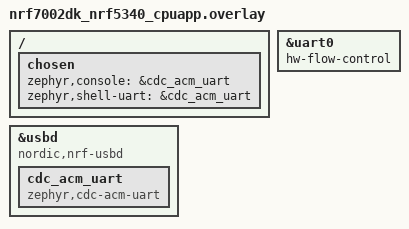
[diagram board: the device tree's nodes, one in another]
/*
 * Copyright (c) 2023 Nordic Semiconductor ASA
 *
 * SPDX-License-Identifier: LicenseRef-Nordic-5-Clause
 */

/ {
	chosen {
		zephyr,console = &cdc_acm_uart;
		zephyr,shell-uart = &cdc_acm_uart;
	};
};

&uart0 {
	status = "okay";
	hw-flow-control;
	// current-speed = < 1000000 >;
	// group1 {
	// 	nordic,drive-mode = <NRF_DRIVE_H0H1>;
	// };
};

zephyr_udc0: &usbd {
	compatible = "nordic,nrf-usbd";
	status = "okay";

	cdc_acm_uart: cdc_acm_uart {
		compatible = "zephyr,cdc-acm-uart";
	};
};
